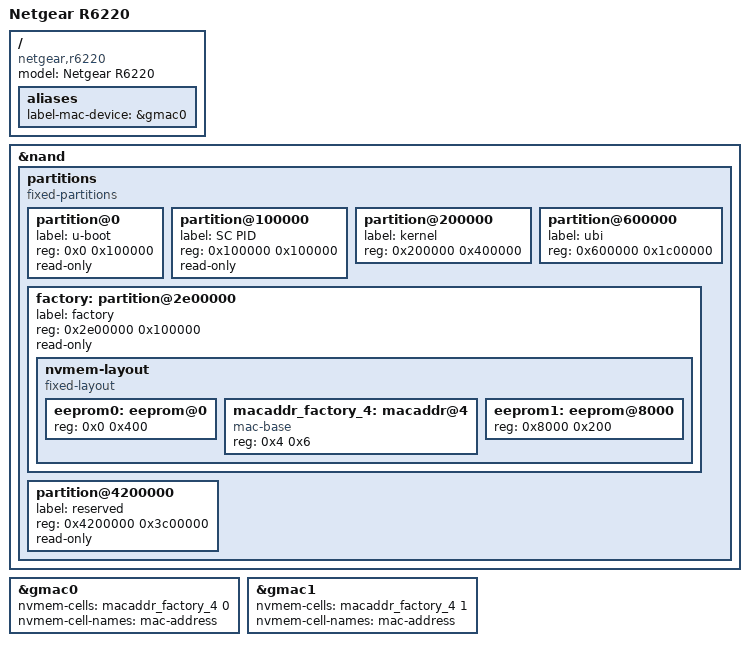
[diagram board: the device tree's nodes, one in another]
// SPDX-License-Identifier: GPL-2.0-only

#include "mt7621_netgear_sercomm_ayx.dtsi"

/ {
	compatible = "netgear,r6220", "mediatek,mt7621-soc";
	model = "Netgear R6220";

	aliases {
		label-mac-device = &gmac0;
	};
};

&nand {
	status = "okay";

	partitions {
		compatible = "fixed-partitions";
		#address-cells = <1>;
		#size-cells = <1>;

		partition@0 {
			label = "u-boot";
			reg = <0x0 0x100000>;
			read-only;
		};

		partition@100000 {
			label = "SC PID";
			reg = <0x100000 0x100000>;
			read-only;
		};

		partition@200000 {
			label = "kernel";
			reg = <0x200000 0x400000>;
		};

		partition@600000 {
			label = "ubi";
			reg = <0x600000 0x1c00000>;
		};

		factory: partition@2e00000 {
			label = "factory";
			reg = <0x2e00000 0x100000>;
			read-only;

			nvmem-layout {
				compatible = "fixed-layout";
				#address-cells = <1>;
				#size-cells = <1>;

				eeprom0: eeprom@0 {
					reg = <0x0 0x400>;
				};

				macaddr_factory_4: macaddr@4 {
					compatible = "mac-base";
					reg = <0x4 0x6>;
					#nvmem-cell-cells = <1>;
				};

				eeprom1: eeprom@8000 {
					reg = <0x8000 0x200>;
				};
			};
		};

		partition@4200000 {
			label = "reserved";
			reg = <0x4200000 0x3c00000>;
			read-only;
		};
	};
};

&gmac0 {
	nvmem-cells = <&macaddr_factory_4 0>;
	nvmem-cell-names = "mac-address";
};

&gmac1 {
	nvmem-cells = <&macaddr_factory_4 1>;
	nvmem-cell-names = "mac-address";
};
